# ADuCM302x register map
Vendor: Analog Devices; Series: ADuCM302x; File version: 1p0
CPU: CM3 r0p1, little endian, no MPU, no FPU, 3 interrupt priority bits
Registers are 32-bit, read-write, reset 0x0 unless marked. A register's access mark holds for its fields unless they carry their own. Offsets are from the block's base; [hi:lo] are bit positions.

## I2C0 — I2C Master/Slave
Base 0x40003000
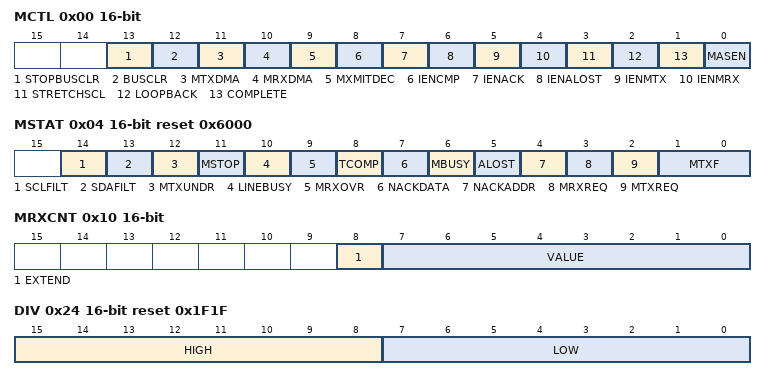
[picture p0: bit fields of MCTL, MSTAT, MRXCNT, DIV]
0x00 MCTL 16-bit — Master Control
  [13] STOPBUSCLR range 0x00000000..0x00000001 — Prestop Bus Clear
  [12] BUSCLR range 0x00000000..0x00000001 — Bus-Clear Enable
  [11] MTXDMA wo range 0x00000000..0x00000001 — Enable Master Tx DMA Request
  [10] MRXDMA wo range 0x00000000..0x00000001 — Enable Master Rx DMA Request
  [9] MXMITDEC range 0x00000000..0x00000001 — Decrement Master Tx FIFO Status When a Byte Txed
  [8] IENCMP range 0x00000000..0x00000001 — Transaction Completed (or Stop Detected) Interrupt Enable
  [7] IENACK range 0x00000000..0x00000001 — ACK Not Received Interrupt Enable
  [6] IENALOST range 0x00000000..0x00000001 — Arbitration Lost Interrupt Enable
  [5] IENMTX range 0x00000000..0x00000001 — Transmit Request Interrupt Enable
  [4] IENMRX range 0x00000000..0x00000001 — Receive Request Interrupt Enable
  [3] STRETCHSCL range 0x00000000..0x00000001 — Stretch SCL Enable
  [2] LOOPBACK range 0x00000000..0x00000001 — Internal Loopback Enable
  [1] COMPLETE range 0x00000000..0x00000001 — Start Back-off Disable
  [0] MASEN range 0x00000000..0x00000001 — Master Enable
0x04 MSTAT 16-bit reset 0x6000 — Master Status
  [14] SCLFILT ro — State of SCL Line
  [13] SDAFILT ro — State of SDA Line
  [12] MTXUNDR ro — Master Transmit Underflow
  [11] MSTOP ro — STOP Driven by This I2C Master
  [10] LINEBUSY ro — Line is Busy
  [9] MRXOVR ro — Master Receive FIFO Overflow
  [8] TCOMP ro — Transaction Complete or Stop Detected
  [7] NACKDATA ro — ACK Not Received in Response to Data Write
  [6] MBUSY ro — Master Busy
  [5] ALOST ro — Arbitration Lost
  [4] NACKADDR ro — ACK Not Received in Response to an Address
  [3] MRXREQ ro — Master Receive Request
  [2] MTXREQ range 0x00000000..0x00000001 — Master Transmit Request/Clear Master Transmit Interrupt
  [1:0] MTXF ro — Master Transmit FIFO Status
    0=FIFO_EMPTY; 2=FIFO_1BYTE (1 byte in FIFO.); 3=FIFO_FULL
0x08 MRX 16-bit — Master Receive Data
  [7:0] VALUE ro — Master Receive Register
0x0C MTX 16-bit — Master Transmit Data
  [7:0] VALUE range 0x00000000..0x000000FF — Master Transmit Register
0x10 MRXCNT 16-bit — Master Receive Data Count
  [8] EXTEND range 0x00000000..0x00000001 — Extended Read
  [7:0] VALUE range 0x00000000..0x000000FF — Receive Count
0x14 MCRXCNT 16-bit — Master Current Receive Data Count
  [7:0] VALUE ro — Current Receive Count
0x18 ADDR1 16-bit — Master Address Byte 1
  [7:0] VALUE range 0x00000000..0x000000FF — Address Byte 1
0x1C ADDR2 16-bit — Master Address Byte 2
  [7:0] VALUE range 0x00000000..0x000000FF — Address Byte 2
0x20 BYT 16-bit — Start Byte
  [7:0] SBYTE range 0x00000000..0x000000FF
0x24 DIV 16-bit reset 0x1F1F — Serial Clock Period Divisor
  [15:8] HIGH range 0x00000000..0x000000FF — Serial Clock High Time
  [7:0] LOW range 0x00000000..0x000000FF — Serial Clock Low Time
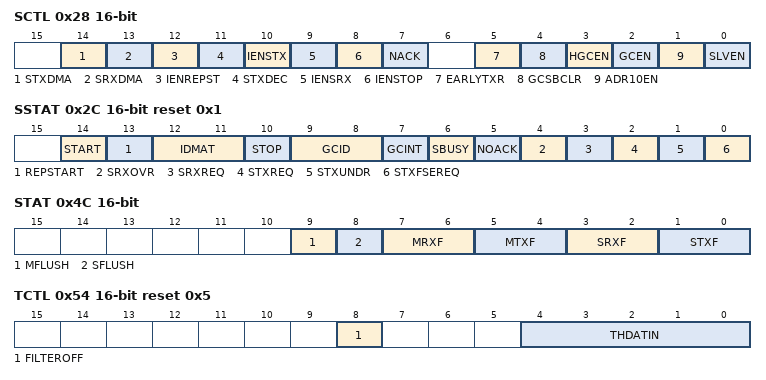
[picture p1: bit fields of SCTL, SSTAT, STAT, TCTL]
0x28 SCTL 16-bit — Slave Control
  [14] STXDMA range 0x00000000..0x00000001 — Enable Slave Tx DMA Request
  [13] SRXDMA range 0x00000000..0x00000001 — Enable Slave Rx DMA Request
  [12] IENREPST range 0x00000000..0x00000001 — Repeated Start Interrupt Enable
  [11] STXDEC range 0x00000000..0x00000001 — Decrement Slave Tx FIFO Status When a Byte is Txed
  [10] IENSTX range 0x00000000..0x00000001 — Slave Transmit Request Interrupt Enable
  [9] IENSRX range 0x00000000..0x00000001 — Slave Receive Request Interrupt Enable
  [8] IENSTOP range 0x00000000..0x00000001 — Stop Condition Detected Interrupt Enable
  [7] NACK range 0x00000000..0x00000001 — NACK Next Communication
  [5] EARLYTXR range 0x00000000..0x00000001 — Early Transmit Request Mode
  [4] GCSBCLR wo range 0x00000000..0x00000001 — General Call Status Bit Clear
  [3] HGCEN range 0x00000000..0x00000001 — Hardware General Call Enable
  [2] GCEN range 0x00000000..0x00000001 — General Call Enable
  [1] ADR10EN range 0x00000000..0x00000001 — Enabled 10-bit Addressing
  [0] SLVEN range 0x00000000..0x00000001 — Slave Enable
0x2C SSTAT 16-bit reset 0x1 — Slave I2C Status/Error/IRQ
  [14] START ro — Start and Matching Address
  [13] REPSTART ro — Repeated Start and Matching Address
  [12:11] IDMAT ro — Device ID Matched
  [10] STOP ro — Stop After Start and Matching Address
  [9:8] GCID ro — General ID
  [7] GCINT ro — General Call Interrupt
  [6] SBUSY ro — Slave Busy
  [5] NOACK ro — ACK Not Generated by the Slave
  [4] SRXOVR ro — Slave Receive FIFO Overflow
  [3] SRXREQ ro — Slave Receive Request
  [2] STXREQ ro — Slave Transmit Request/Slave Transmit Interrupt
  [1] STXUNDR ro — Slave Transmit FIFO Underflow
  [0] STXFSEREQ range 0x00000000..0x00000001 — Slave Tx FIFO Status or Early Request
0x30 SRX 16-bit — Slave Receive
  [7:0] VALUE ro — Slave Receive Register
0x34 STX 16-bit — Slave Transmit
  [7:0] VALUE range 0x00000000..0x000000FF — Slave Transmit Register
0x38 ALT 16-bit — Hardware General Call ID
  [7:0] ID range 0x00000000..0x000000FF — Slave Alt
0x3C ID0 16-bit — First Slave Address Device ID
  [7:0] VALUE range 0x00000000..0x000000FF — Slave Device ID 0
0x40 ID1 16-bit — Second Slave Address Device ID
  [7:0] VALUE range 0x00000000..0x000000FF — Slave Device ID 1
0x44 ID2 16-bit — Third Slave Address Device ID
  [7:0] VALUE range 0x00000000..0x000000FF — Slave Device ID 2
0x48 ID3 16-bit — Fourth Slave Address Device ID
  [7:0] VALUE range 0x00000000..0x000000FF — Slave Device ID 3
0x4C STAT 16-bit — Master and Slave FIFO Status
  [9] MFLUSH wo range 0x00000000..0x00000001 — Flush the Master Transmit FIFO
  [8] SFLUSH wo range 0x00000000..0x00000001 — Flush the Slave Transmit FIFO
  [7:6] MRXF ro — Master Receive FIFO Status
  [5:4] MTXF ro — Master Transmit FIFO Status
  [3:2] SRXF ro — Slave Receive FIFO Status
  [1:0] STXF ro — Slave Transmit FIFO Status
0x50 SHCTL 16-bit — Shared Control
  [0] RST wo range 0x00000000..0x00000001 — Reset START STOP Detect Circuit
0x54 TCTL 16-bit reset 0x5 — Timing Control Register
  [8] FILTEROFF — Input Filter Control
  [4:0] THDATIN range 0x00000000..0x0000001F — Data in Hold Start
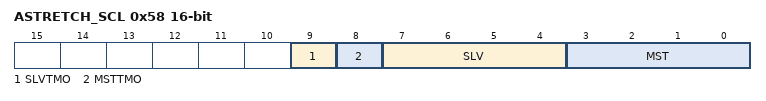
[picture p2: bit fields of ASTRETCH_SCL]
0x58 ASTRETCH_SCL 16-bit — Automatic Stretch SCL
  [9] SLVTMO ro — Slave Automatic Stretch Timeout
  [8] MSTTMO ro — Master Automatic Stretch Timeout
  [7:4] SLV range 0x00000000..0x0000000F — Slave Automatic Stretch Mode
  [3:0] MST range 0x00000000..0x0000000F — Master Automatic Stretch Mode

## Notices in the file
Copyright (c) 2014-2017 Analog Devices, Inc.  All Rights Reserved.
This software is proprietary and confidential to Analog Devices, Inc.
and its licensors.
